# SA3_SS_SA_UL_0_SA_UL_RNG_40910000h register map
Vendor: Texas Instruments
Peripheral module from a debugger description file (folder am62D).
Registers are 32-bit, write-only, reset 0x0 unless marked. A register's access mark holds for its fields unless they carry their own. Offsets are as the file gives them; lines under a group give offsets from that group; [hi:lo] are bit positions; {n}, {i} and the like mark numbered series; 'fields as' and 'values as' point back to an identical list; <NAME> marks a mode.

## sa_ul_rng
{0x0+4i} sa_ul_rng_TRNG_INPUT_{i} (i=0..3) — Please refer to eip76d HW Reference Manual for details
  [31:0] TRNG_INPUT_{i}
{0x0+4i} sa_ul_rng_TRNG_OUTPUT_{i} ro (i=0..3) — Please refer to eip76d HW Reference Manual for details
  [31:0] TRNG_OUTPUT_{i}
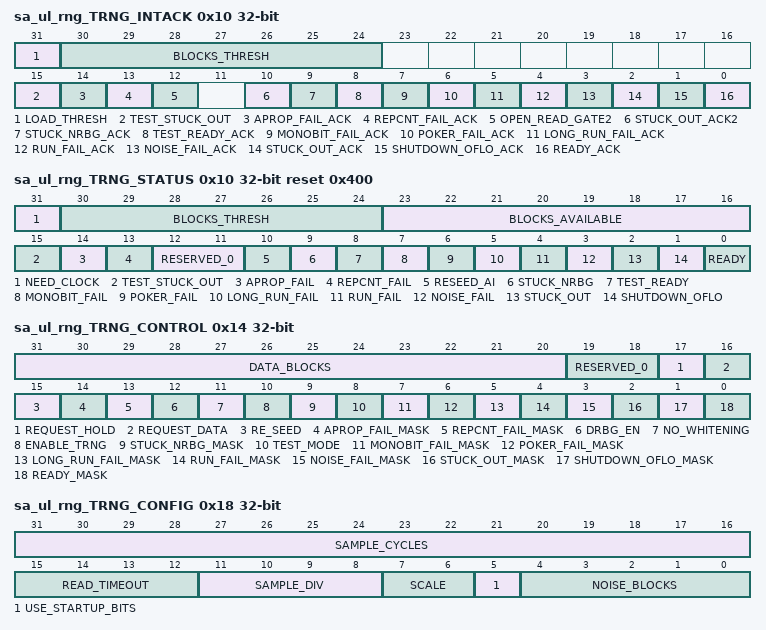
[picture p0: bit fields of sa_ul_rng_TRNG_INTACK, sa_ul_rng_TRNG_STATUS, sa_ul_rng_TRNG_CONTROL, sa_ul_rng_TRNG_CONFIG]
0x10 sa_ul_rng_TRNG_INTACK — Please refer to eip76d HW Reference Manual for details
  [31] LOAD_THRESH — Please refer to eip76d HW Reference Manual for details
  [30:24] BLOCKS_THRESH — Please refer to eip76d HW Reference Manual for details
  [15] TEST_STUCK_OUT — Please refer to eip76d HW Reference Manual for details
  [14] APROP_FAIL_ACK — Please refer to eip76d HW Reference Manual for details
  [13] REPCNT_FAIL_ACK — Please refer to eip76d HW Reference Manual for details
  [12] OPEN_READ_GATE2 — Please refer to eip76d HW Reference Manual for details
  [10] STUCK_OUT_ACK2 — Please refer to eip76d HW Reference Manual for details
  [9] STUCK_NRBG_ACK — Please refer to eip76d HW Reference Manual for details
  [8] TEST_READY_ACK — Please refer to eip76d HW Reference Manual for details
  [7] MONOBIT_FAIL_ACK — Please refer to eip76d HW Reference Manual for details
  [6] POKER_FAIL_ACK — Please refer to eip76d HW Reference Manual for details
  [5] LONG_RUN_FAIL_ACK — Please refer to eip76d HW Reference Manual for details
  [4] RUN_FAIL_ACK — Please refer to eip76d HW Reference Manual for details
  [3] NOISE_FAIL_ACK — Please refer to eip76d HW Reference Manual for details
  [2] STUCK_OUT_ACK — Please refer to eip76d HW Reference Manual for details
  [1] SHUTDOWN_OFLO_ACK — Please refer to eip76d HW Reference Manual for details
  [0] READY_ACK — Please refer to eip76d HW Reference Manual for details
0x10 sa_ul_rng_TRNG_INTACK_secure_mode — Please refer to eip76d HW Reference Manual for details
  [14:0] READY
0x10 sa_ul_rng_TRNG_STATUS ro reset 0x400 — Please refer to eip76d HW Reference Manual for details
  [31] NEED_CLOCK — Please refer to eip76d HW Reference Manual for details
  [30:24] BLOCKS_THRESH — Please refer to eip76d HW Reference Manual for details
  [23:16] BLOCKS_AVAILABLE — Please refer to eip76d HW Reference Manual for details
  [15] TEST_STUCK_OUT — Please refer to eip76d HW Reference Manual for details
  [14] APROP_FAIL — Please refer to eip76d HW Reference Manual for details
  [13] REPCNT_FAIL — Please refer to eip76d HW Reference Manual for details
  [12:11] RESERVED_0 — Please refer to eip76d HW Reference Manual for details
  [10] RESEED_AI — Please refer to eip76d HW Reference Manual for details
  [9] STUCK_NRBG — Please refer to eip76d HW Reference Manual for details
  [8] TEST_READY — Please refer to eip76d HW Reference Manual for details
  [7] MONOBIT_FAIL — Please refer to eip76d HW Reference Manual for details
  [6] POKER_FAIL — Please refer to eip76d HW Reference Manual for details
  [5] LONG_RUN_FAIL — Please refer to eip76d HW Reference Manual for details
  [4] RUN_FAIL — Please refer to eip76d HW Reference Manual for details
  [3] NOISE_FAIL — Please refer to eip76d HW Reference Manual for details
  [2] STUCK_OUT — Please refer to eip76d HW Reference Manual for details
  [1] SHUTDOWN_OFLO — Please refer to eip76d HW Reference Manual for details
  [0] READY — Please refer to eip76d HW Reference Manual for details
0x14 sa_ul_rng_TRNG_CONTROL access per field — Please refer to eip76d HW Reference Manual for details
  [31:20] DATA_BLOCKS rw — Please refer to eip76d HW Reference Manual for details
  [19:18] RESERVED_0 ro — Please refer to eip76d HW Reference Manual for details
  [17] REQUEST_HOLD rw — Please refer to eip76d HW Reference Manual for details
  [16] REQUEST_DATA wo — Please refer to eip76d HW Reference Manual for details
  [15] RE_SEED rw — Please refer to eip76d HW Reference Manual for details
  [14] APROP_FAIL_MASK rw — Please refer to eip76d HW Reference Manual for details
  [13] REPCNT_FAIL_MASK rw — Please refer to eip76d HW Reference Manual for details
  [12] DRBG_EN rw — Please refer to eip76d HW Reference Manual for details
  [11] NO_WHITENING rw — Please refer to eip76d HW Reference Manual for details
  [10] ENABLE_TRNG rw — Please refer to eip76d HW Reference Manual for details
  [9] STUCK_NRBG_MASK rw — Please refer to eip76d HW Reference Manual for details
  [8] TEST_MODE rw — Please refer to eip76d HW Reference Manual for details
  [7] MONOBIT_FAIL_MASK rw — Please refer to eip76d HW Reference Manual for details
  [6] POKER_FAIL_MASK rw — Please refer to eip76d HW Reference Manual for details
  [5] LONG_RUN_FAIL_MASK rw — Please refer to eip76d HW Reference Manual for details
  [4] RUN_FAIL_MASK rw — Please refer to eip76d HW Reference Manual for details
  [3] NOISE_FAIL_MASK rw — Please refer to eip76d HW Reference Manual for details
  [2] STUCK_OUT_MASK rw — Please refer to eip76d HW Reference Manual for details
  [1] SHUTDOWN_OFLO_MASK rw — Please refer to eip76d HW Reference Manual for details
  [0] READY_MASK rw — Please refer to eip76d HW Reference Manual for details
0x18 sa_ul_rng_TRNG_CONFIG rw — Please refer to eip76d HW Reference Manual for details
  [31:16] SAMPLE_CYCLES — Please refer to eip76d HW Reference Manual for details
  [15:12] READ_TIMEOUT — Please refer to eip76d HW Reference Manual for details
  [11:8] SAMPLE_DIV — Please refer to eip76d HW Reference Manual for details
  [7:6] SCALE — Please refer to eip76d HW Reference Manual for details
  [5] USE_STARTUP_BITS — Please refer to eip76d HW Reference Manual for details
  [4:0] NOISE_BLOCKS — Please refer to eip76d HW Reference Manual for details
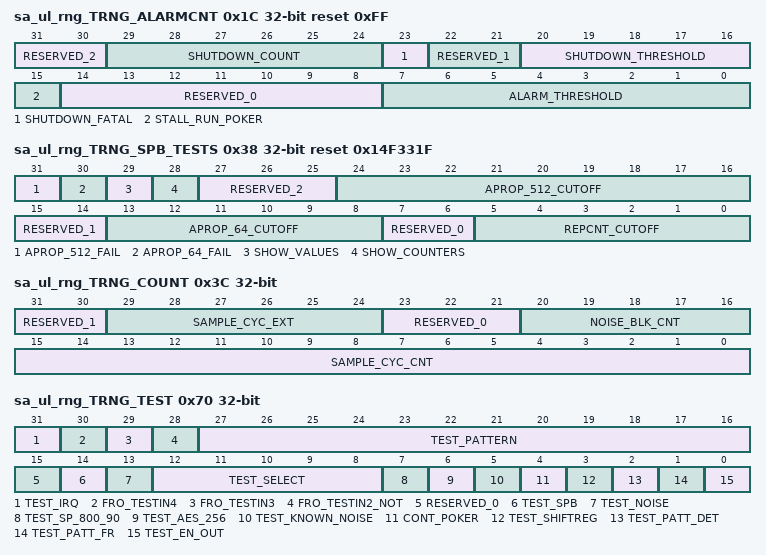
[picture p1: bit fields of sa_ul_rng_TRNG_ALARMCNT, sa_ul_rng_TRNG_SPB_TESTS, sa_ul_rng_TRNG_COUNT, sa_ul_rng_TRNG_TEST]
0x1C sa_ul_rng_TRNG_ALARMCNT access per field reset 0xFF — Please refer to eip76d HW Reference Manual for details
  [31:30] RESERVED_2 ro — Please refer to eip76d HW Reference Manual for details
  [29:24] SHUTDOWN_COUNT ro — Please refer to eip76d HW Reference Manual for details
  [23] SHUTDOWN_FATAL rw — Please refer to eip76d HW Reference Manual for details
  [22:21] RESERVED_1 ro — Please refer to eip76d HW Reference Manual for details
  [20:16] SHUTDOWN_THRESHOLD rw — Please refer to eip76d HW Reference Manual for details
  [15] STALL_RUN_POKER rw — Please refer to eip76d HW Reference Manual for details
  [14:8] RESERVED_0 ro — Please refer to eip76d HW Reference Manual for details
  [7:0] ALARM_THRESHOLD rw — Please refer to eip76d HW Reference Manual for details
0x20 sa_ul_rng_TRNG_FROENABLE rw reset 0xFF — Please refer to eip76d HW Reference Manual for details
  [7:0] TRNG_FROENABLE
0x24 sa_ul_rng_TRNG_FRODETUNE rw — Please refer to eip76d HW Reference Manual for details
  [7:0] TRNG_FRODETUNE
0x28 sa_ul_rng_TRNG_ALARMMASK rw — Please refer to eip76d HW Reference Manual for details
  [7:0] TRNG_ALARMMASK
0x2C sa_ul_rng_TRNG_ALARMSTOP rw — Please refer to eip76d HW Reference Manual for details
  [7:0] TRNG_ALARMSTOP
0x30 sa_ul_rng_TRNG_RAW_L rw — Please refer to eip76d HW Reference Manual for details
  [31:0] TRNG_RAW_L
0x34 sa_ul_rng_TRNG_RAW_H rw — Please refer to eip76d HW Reference Manual for details
  [31:0] TRNG_RAW_H
0x38 sa_ul_rng_TRNG_SPB_TESTS access per field reset 0x14F331F — Please refer to eip76d HW Reference Manual for details
  [31] APROP_512_FAIL rw — Please refer to eip76d HW Reference Manual for details
  [30] APROP_64_FAIL rw — Please refer to eip76d HW Reference Manual for details
  [29] SHOW_VALUES rw — Please refer to eip76d HW Reference Manual for details
  [28] SHOW_COUNTERS rw — Please refer to eip76d HW Reference Manual for details
  [27:25] RESERVED_2 ro — Please refer to eip76d HW Reference Manual for details
  [24:16] APROP_512_CUTOFF rw — Please refer to eip76d HW Reference Manual for details
  [15:14] RESERVED_1 ro — Please refer to eip76d HW Reference Manual for details
  [13:8] APROP_64_CUTOFF rw — Please refer to eip76d HW Reference Manual for details
  [7:6] RESERVED_0 ro — Please refer to eip76d HW Reference Manual for details
  [5:0] REPCNT_CUTOFF rw — Please refer to eip76d HW Reference Manual for details
0x3C sa_ul_rng_TRNG_COUNT ro — Please refer to eip76d HW Reference Manual for details
  [31:30] RESERVED_1 — Please refer to eip76d HW Reference Manual for details
  [29:24] SAMPLE_CYC_EXT — Please refer to eip76d HW Reference Manual for details
  [23:21] RESERVED_0 — Please refer to eip76d HW Reference Manual for details
  [20:16] NOISE_BLK_CNT — Please refer to eip76d HW Reference Manual for details
  [15:0] SAMPLE_CYC_CNT — Please refer to eip76d HW Reference Manual for details
{0x40+4i} sa_ul_rng_TRNG_PS_AI_{i} (i=0..11) — Please refer to eip76d HW Reference Manual for details
  [31:0] VECTOR
0x70 sa_ul_rng_TRNG_TEST access per field — Please refer to eip76d HW Reference Manual for details
  [31] TEST_IRQ rw — Please refer to eip76d HW Reference Manual for details
  [30] FRO_TESTIN4 rw — Please refer to eip76d HW Reference Manual for details
  [29] FRO_TESTIN3 rw — Please refer to eip76d HW Reference Manual for details
  [28] FRO_TESTIN2_NOT rw — Please refer to eip76d HW Reference Manual for details
  [27:16] TEST_PATTERN rw — Please refer to eip76d HW Reference Manual for details
  [15] RESERVED_0 ro — Please refer to eip76d HW Reference Manual for details
  [14] TEST_SPB rw — Please refer to eip76d HW Reference Manual for details
  [13] TEST_NOISE rw — Please refer to eip76d HW Reference Manual for details
  [12:8] TEST_SELECT rw — Please refer to eip76d HW Reference Manual for details
  [7] TEST_SP_800_90 rw — Please refer to eip76d HW Reference Manual for details
  [6] TEST_AES_256 rw — Please refer to eip76d HW Reference Manual for details
  [5] TEST_KNOWN_NOISE rw — Please refer to eip76d HW Reference Manual for details
  [4] CONT_POKER rw — Please refer to eip76d HW Reference Manual for details
  [3] TEST_SHIFTREG rw — Please refer to eip76d HW Reference Manual for details
  [2] TEST_PATT_DET rw — Please refer to eip76d HW Reference Manual for details
  [1] TEST_PATT_FR rw — Please refer to eip76d HW Reference Manual for details
  [0] TEST_EN_OUT rw — Please refer to eip76d HW Reference Manual for details
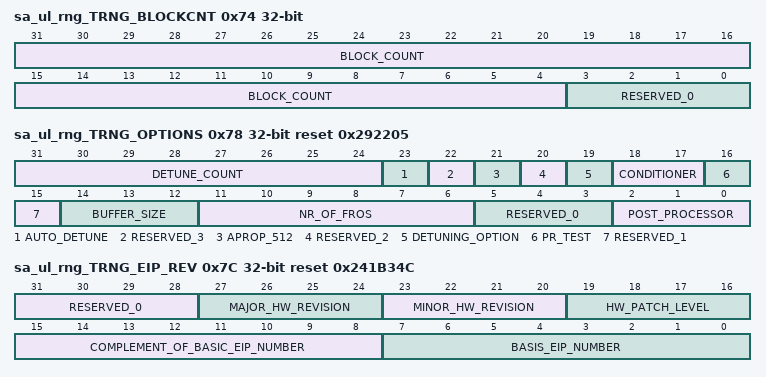
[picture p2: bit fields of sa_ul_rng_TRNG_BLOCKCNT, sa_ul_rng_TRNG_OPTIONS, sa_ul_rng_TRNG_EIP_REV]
0x74 sa_ul_rng_TRNG_BLOCKCNT access per field — Please refer to eip76d HW Reference Manual for details
  [31:4] BLOCK_COUNT rw — Please refer to eip76d HW Reference Manual for details
  [3:0] RESERVED_0 ro — Please refer to eip76d HW Reference Manual for details
0x78 sa_ul_rng_TRNG_OPTIONS access per field reset 0x292205 — Please refer to eip76d HW Reference Manual for details
  [31:24] DETUNE_COUNT rw — Please refer to eip76d HW Reference Manual for details
  [23] AUTO_DETUNE rw — Please refer to eip76d HW Reference Manual for details
  [22] RESERVED_3 ro — Please refer to eip76d HW Reference Manual for details
  [21] APROP_512 ro — Please refer to eip76d HW Reference Manual for details
  [20] RESERVED_2 ro — Please refer to eip76d HW Reference Manual for details
  [19] DETUNING_OPTION ro — Please refer to eip76d HW Reference Manual for details
  [18:17] CONDITIONER ro — Please refer to eip76d HW Reference Manual for details
  [16] PR_TEST ro — Please refer to eip76d HW Reference Manual for details
  [15] RESERVED_1 ro — Please refer to eip76d HW Reference Manual for details
  [14:12] BUFFER_SIZE ro — Please refer to eip76d HW Reference Manual for details
  [11:6] NR_OF_FROS ro — Please refer to eip76d HW Reference Manual for details
  [5:3] RESERVED_0 ro — Please refer to eip76d HW Reference Manual for details
  [2:0] POST_PROCESSOR ro — Please refer to eip76d HW Reference Manual for details
0x7C sa_ul_rng_TRNG_EIP_REV ro reset 0x241B34C — Please refer to eip76d HW Reference Manual for details
  [31:28] RESERVED_0 — Please refer to eip76d HW Reference Manual for details
  [27:24] MAJOR_HW_REVISION — Please refer to eip76d HW Reference Manual for details
  [23:20] MINOR_HW_REVISION — Please refer to eip76d HW Reference Manual for details
  [19:16] HW_PATCH_LEVEL — Please refer to eip76d HW Reference Manual for details
  [15:8] COMPLEMENT_OF_BASIC_EIP_NUMBER — Please refer to eip76d HW Reference Manual for details
  [7:0] BASIS_EIP_NUMBER — Please refer to eip76d HW Reference Manual for details
